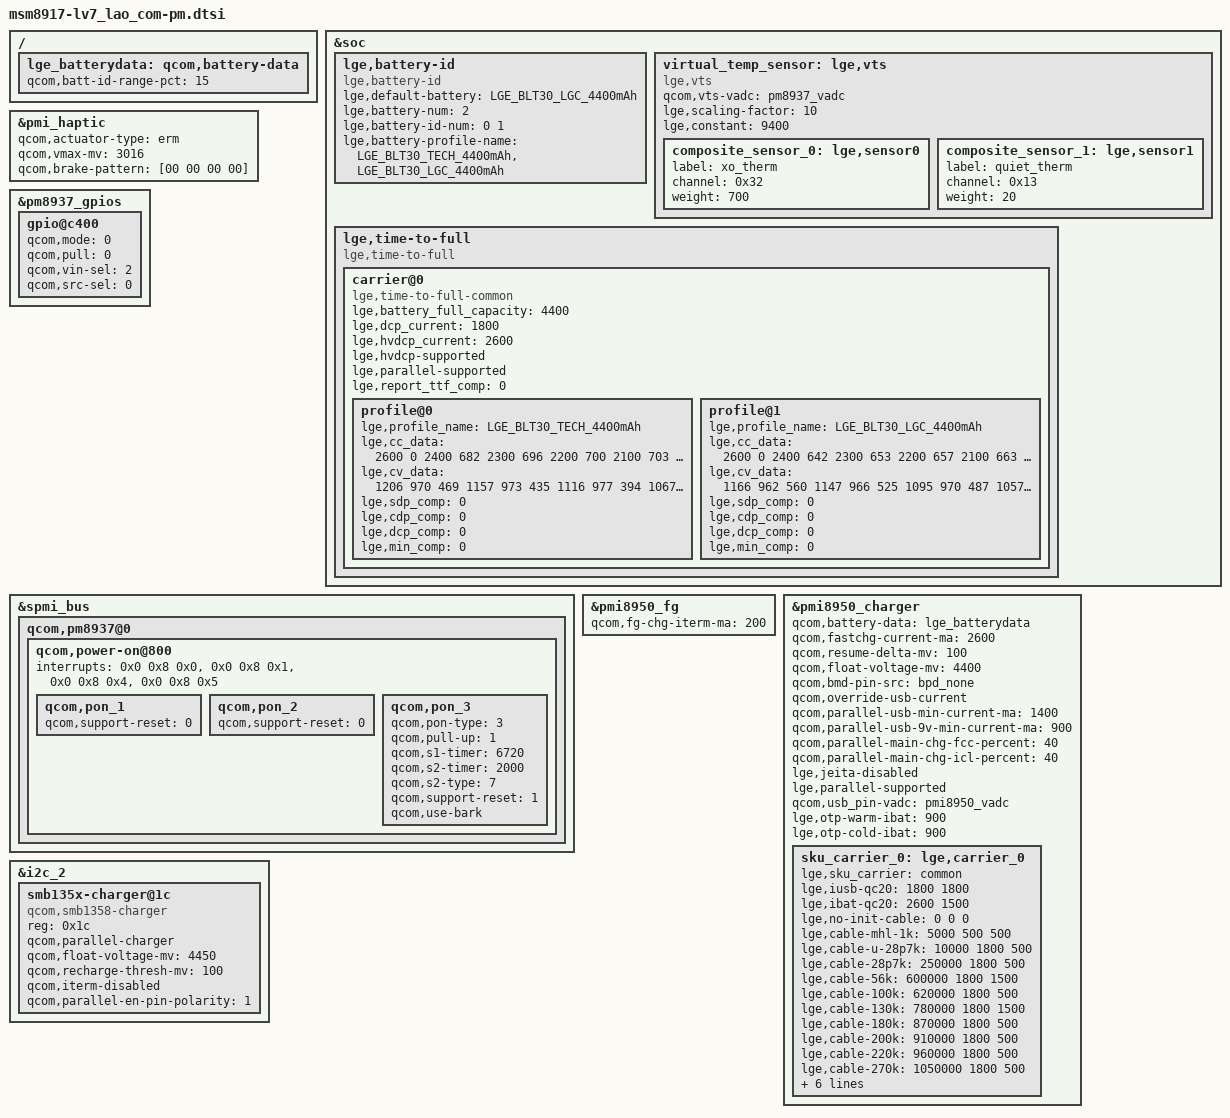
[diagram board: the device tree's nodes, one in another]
/*
 * Copyright (c) 2016, The Linux Foundation. All rights reserved.
 *
 * This program is free software; you can redistribute it and/or modify
 * it under the terms of the GNU General Public License version 2 and
 * only version 2 as published by the Free Software Foundation.
 *
 * This program is distributed in the hope that it will be useful,
 * but WITHOUT ANY WARRANTY; without even the implied warranty of
 * MERCHANTABILITY or FITNESS FOR A PARTICULAR PURPOSE.  See the
 * GNU General Public License for more details.
 */

/{
	lge_batterydata: qcom,battery-data {
		qcom,batt-id-range-pct = <15>;
		#include "../battery_profile/LGE_BLT30_LGC_4400mAh.dtsi"
		#include "../battery_profile/LGE_BLT30_TECH_4400mAh.dtsi"
	};
};

&soc {
	lge,battery-id{
		compatible = "lge,battery-id";
		/delete-property/ lge,restrict-mode-enabled;
		/*default battery profile*/
		lge,default-battery = "LGE_BLT30_LGC_4400mAh";
		/*Total number of combined of battery cell and battery id */
		lge,battery-num = <2>;
		/* battery id and battery profile match numbers */
		lge,battery-id-num = <0 1>;
		/* battery profile */
		lge,battery-profile-name = "LGE_BLT30_TECH_4400mAh",
						"LGE_BLT30_LGC_4400mAh";
	};

	/* vts = (0.70*xo_therm) + (0.02*quiet_therm) + 9.4 */
	virtual_temp_sensor: lge,vts {
		compatible = "lge,vts";
		qcom,vts-vadc = <&pm8937_vadc>;
		lge,scaling-factor= <10>;
		lge,constant = <9400>;
		composite_sensor_0: lge,sensor0 {
			label = "xo_therm";
			channel = <0x32>;
			weight = <700>;
		};
		composite_sensor_1: lge,sensor1 {
			label = "quiet_therm";
			channel = <0x13>;
			weight = <20>;
		};
	};

	/* time to full */
	lge,time-to-full {
		compatible = "lge,time-to-full";
		carrier@0 {
			compatible = "lge,time-to-full-common";
			lge,battery_full_capacity = <4400>;
			lge,dcp_current = <1800>;
			lge,hvdcp_current = <2600>;
			lge,hvdcp-supported;
			lge,parallel-supported;
			lge,report_ttf_comp = <0>;
			profile@0 {
				lge,profile_name = "LGE_BLT30_TECH_4400mAh";
					    /* current  soc */
				lge,cc_data = < 2600	0
						2400	682
						2300	696
						2200	700
						2100	703
						1900	706
						1600	920
						1350	942
						1175	959>;
					    /* current  soc    time */
				lge,cv_data = < 1206	970	469
						1157	973	435
						1116	977	394
						1067	980	354
						1007	983	311
						950	986	267
						896	989	218
						842	992	168
						787	995	116
						742	998	59
						687	1000	0>;
				lge,sdp_comp = <0>;
				lge,cdp_comp = <0>;
				lge,dcp_comp = <0>;
				lge,min_comp = <0>;
			};
			profile@1 {
				lge,profile_name = "LGE_BLT30_LGC_4400mAh";
					    /* current  soc */
				lge,cc_data = < 2600	0
						2400	642
						2300	653
						2200	657
						2100	663
						1900	678
						1600	898
						1350	926
						1175	946>;
					    /* current  soc    time */
				lge,cv_data = < 1166	962	560
						1147	966	525
						1095	970	487
						1057	973	448
						996	977	407
						958	980	364
						915	983	319
						861	986	272
						818	989	223
						771	992	172
						727	995	117
						685	998	60
						644	1000	0>;
				lge,sdp_comp = <0>;
				lge,cdp_comp = <0>;
				lge,dcp_comp = <0>;
				lge,min_comp = <0>;
			};
		};
	};
};

&pmi_haptic{
	status = "okay";
	qcom,actuator-type = "erm";
	qcom,vmax-mv = <3016>;
	qcom,brake-pattern = [00 00 00 00];
};

&pm8937_gpios {
	gpio@c400 {
		qcom,mode = <0>;
		qcom,pull = <0>;
		qcom,vin-sel = <2>;
		qcom,src-sel = <0>;
		status = "okay";
	};
};

&spmi_bus {
	qcom,pm8937@0 {
		qcom,power-on@800 {
			interrupts = <0x0 0x8 0x0>,
				     <0x0 0x8 0x1>,
				     <0x0 0x8 0x4>,
				     <0x0 0x8 0x5>;
			interrupt-names = "kpdpwr", "resin",
				"resin-bark", "kpdpwr-resin-bark";

			qcom,pon_1 {
				status = "ok";
				qcom,support-reset = <0>;
			};
			qcom,pon_2 {
				status = "ok";
				qcom,support-reset = <0>;
			};
			qcom,pon_3 {
				status = "ok";
				qcom,pon-type = <3>;
				qcom,pull-up = <1>;
				qcom,s1-timer = <6720>;
				qcom,s2-timer = <2000>;
				qcom,s2-type = <7>;
				qcom,support-reset = <1>;
				qcom,use-bark;
			};
		};
	};
};

&pmi8950_fg {
	qcom,fg-chg-iterm-ma = <200>;
};

&pmi8950_charger {
	qcom,battery-data = <&lge_batterydata>;
	qcom,fastchg-current-ma = <2600>;
	qcom,resume-delta-mv = <100>;
	qcom,float-voltage-mv = <4400>;
	qcom,bmd-pin-src = "bpd_none";
	qcom,override-usb-current;
	qcom,parallel-usb-min-current-ma = <1400>;
	qcom,parallel-usb-9v-min-current-ma = <900>;
	qcom,parallel-main-chg-fcc-percent = <40>;
	qcom,parallel-main-chg-icl-percent = <40>;
	lge,jeita-disabled;
	lge,parallel-supported;

	qcom,usb_pin-vadc = <&pmi8950_vadc>;

	lge,otp-warm-ibat = <900>;
	lge,otp-cold-ibat = <900>;

	sku_carrier_0:	lge,carrier_0 {
		lge,sku_carrier = "common";
		lge,iusb-qc20 = <1800 1800>;
		lge,ibat-qc20 = <2600 1500>;

		/* ref resistance 200K */
		lge,no-init-cable = <0 0 0>;
		lge,cable-mhl-1k = <5000 500 500>;
		lge,cable-u-28p7k = <10000 1800 500>;
		lge,cable-28p7k = <250000 1800 500>;
		lge,cable-56k = <600000 1800 1500>;
		lge,cable-100k = <620000 1800 500>;
		lge,cable-130k = <780000 1800 1500>;
		lge,cable-180k = <870000 1800 500>;
		lge,cable-200k = <910000 1800 500>;
		lge,cable-220k = <960000 1800 500>;
		lge,cable-270k = <1050000 1800 500>;
		lge,cable-330k = <1150000 1800 500>;
		lge,cable-620k = <1380000 1800 500>;
		lge,cable-910k = <1630000 1800 1500>;
		lge,cable-none = <1900000 1800  500>;

		lge,fastchg-current-ma = <2600>;
		lge,usb-max-current-ma = <1800>;
	};
};

&i2c_2 {
	/* Parallel-charger configuration */
	smb135x-charger@1c{
		status = "ok";
		compatible = "qcom,smb1358-charger";
		reg = <0x1c>;
		qcom,parallel-charger;
		qcom,float-voltage-mv = <4450>;
		qcom,recharge-thresh-mv = <100>;
		qcom,iterm-disabled;
		qcom,parallel-en-pin-polarity = <1>;
	};
};
